# max32665 register map
Vendor: Maxim-Integrated; Series: ARMCM3; File version: 1.0
CPU: CM4 r2p1, little endian, MPU, FPU, 3 interrupt priority bits
Registers are 32-bit, read-write, reset 0x0 unless marked. A register's access mark holds for its fields unless they carry their own. Offsets are from the block's base; [hi:lo] are bit positions; {n}, {i} and the like mark numbered series; 'fields as' and 'values as' point back to an identical list.

## PTG — Pulse Train Generation
Base 0x4003C000
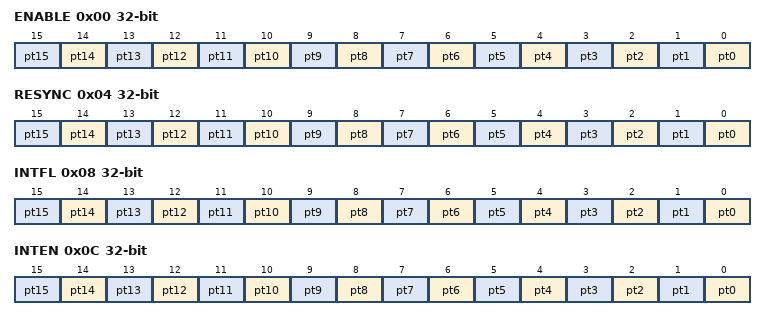
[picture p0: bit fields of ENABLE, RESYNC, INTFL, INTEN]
0x00 ENABLE — Global Enable/Disable Controls for All Pulse Trains
  [n] pt{n} (n=0..15) — Enable/Disable control for PT{n}
0x04 RESYNC — Global Resync (All Pulse Trains) Control
  [n] pt{n} (n=0..15) — Resync control for PT{n}
0x08 INTFL — Pulse Train Interrupt Flags
  [n] pt{n} (n=0..15) — Pulse Train {n} Stopped Interrupt Flag
0x0C INTEN — Pulse Train Interrupt Enable/Disable
  [n] pt{n} (n=0..15) — Pulse Train {n} Stopped Interrupt Enable/Disable
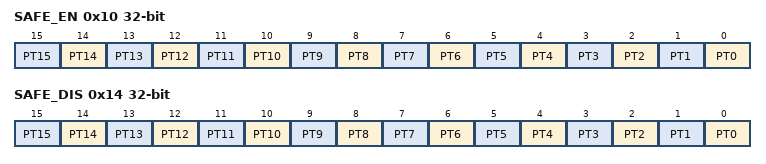
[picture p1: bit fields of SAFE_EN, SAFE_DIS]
0x10 SAFE_EN wo — Pulse Train Global Safe Enable.
  [n] PT{n} (n=0..15)
0x14 SAFE_DIS wo — Pulse Train Global Safe Disable.
  [n] PT{n} (n=0..15)

## SEMA — The Semaphore peripheral allows multiple cores in a system to cooperate when accessing shred resources. The peripheral contains eight semaphores that can be atomically set and cleared. It is left to the discretion of the software architect to decide how and when the semaphores are used and how they are allocated. Existing hardware does not have to be modified for this type of cooperative sharing, and the use of semaphores is exclusively within the software domain.
Base 0x4003E000
{0x0+4i} SEMAPHORES[{i}] (i=0..7) — Read to test and set, returns prior value. Write 0 to clear semaphore.
  [0] sema
0x100 status — Semaphore status bits. 0 indicates the semaphore is free, 1 indicates taken.
  [7:0] STATUS

## SIMO — Single Inductor Multiple Output Switching Converter
Base 0x40004400
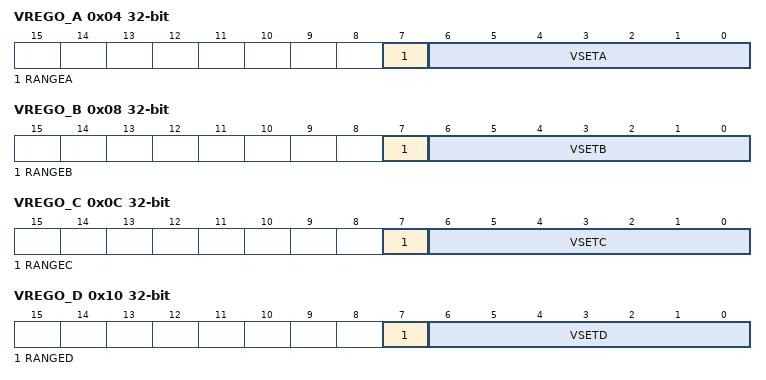
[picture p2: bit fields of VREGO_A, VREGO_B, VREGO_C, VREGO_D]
0x04 VREGO_A — Buck Voltage Regulator A Control Register
  [7] RANGEA — Regulator Output Range Set
    0=low (Low output voltage range); 1=High output voltage range
  [6:0] VSETA — Regulator Output Voltage Setting
0x08 VREGO_B — Buck Voltage Regulator B Control Register
  [7] RANGEB — Regulator Output Range Set
    values as VREGO_A.RANGEA
  [6:0] VSETB — Regulator Output Voltage Setting
0x0C VREGO_C — Buck Voltage Regulator C Control Register
  [7] RANGEC — Regulator Output Range Set
    values as VREGO_A.RANGEA
  [6:0] VSETC — Regulator Output Voltage Setting
0x10 VREGO_D — Buck Voltage Regulator D Control Register
  [7] RANGED — Regulator Output Range Set
    values as VREGO_A.RANGEA
  [6:0] VSETD — Regulator Output Voltage Setting
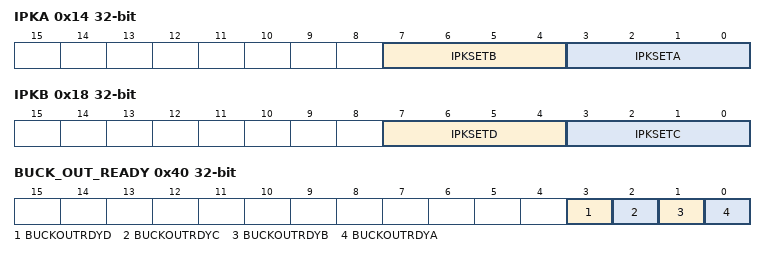
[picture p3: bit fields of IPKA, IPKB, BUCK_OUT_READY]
0x14 IPKA — High Side FET Peak Current VREGO_A/VREGO_B Register
  [7:4] IPKSETB — Voltage Regulator Peak Current Setting
  [3:0] IPKSETA — Voltage Regulator Peak Current Setting
0x18 IPKB — High Side FET Peak Current VREGO_C/VREGO_D Register
  [7:4] IPKSETD — Voltage Regulator Peak Current Setting
  [3:0] IPKSETC — Voltage Regulator Peak Current Setting
0x1C MAXTON — Maximum High Side FET Time On Register
  [3:0] TONSET — Sets the maximum on time for the high side FET, each increment represents 500ns
0x20 ILOAD_A ro — Buck Cycle Count VREGO_A Register
  [7:0] ILOADA — Number of buck cycles that occur within the cycle clock
0x24 ILOAD_B ro — Buck Cycle Count VREGO_B Register
  [7:0] ILOADB — Number of buck cycles that occur within the cycle clock
0x28 ILOAD_C ro — Buck Cycle Count VREGO_C Register
  [7:0] ILOADC — Number of buck cycles that occur within the cycle clock
0x2C ILOAD_D ro — Buck Cycle Count VREGO_D Register
  [7:0] ILOADD — Number of buck cycles that occur within the cycle clock
0x30 BUCK_ALERT_THR_A — Buck Cycle Count Alert VERGO_A Register
  [7:0] BUCKTHRA — Threshold for ILOADA to generate the BUCK_ALERT
0x34 BUCK_ALERT_THR_B — Buck Cycle Count Alert VERGO_B Register
  [7:0] BUCKTHRB — Threshold for ILOADB to generate the BUCK_ALERT
0x38 BUCK_ALERT_THR_C — Buck Cycle Count Alert VERGO_C Register
  [7:0] BUCKTHRC — Threshold for ILOADC to generate the BUCK_ALERT
0x3C BUCK_ALERT_THR_D — Buck Cycle Count Alert VERGO_D Register
  [7:0] BUCKTHRD — Threshold for ILOADD to generate the BUCK_ALERT
0x40 BUCK_OUT_READY ro — Buck Regulator Output Ready Register
  [all] fields
    0=notrdy (Output voltage not in range); 1=rdy (Output voltage in range)
  [3] BUCKOUTRDYD — When set, indicates that the output voltage has reached its regulated value
  [2] BUCKOUTRDYC — When set, indicates that the output voltage has reached its regulated value
  [1] BUCKOUTRDYB — When set, indicates that the output voltage has reached its regulated value
  [0] BUCKOUTRDYA — When set, indicates that the output voltage has reached its regulated value
0x44 ZERO_CROSS_CAL_A ro — Zero Cross Calibration VERGO_A Register
  [3:0] ZXCALA — Zero Cross Calibrartion Value VREGO_A
0x48 ZERO_CROSS_CAL_B ro — Zero Cross Calibration VERGO_B Register
  [3:0] ZXCALB — Zero Cross Calibrartion Value VREGO_B
0x4C ZERO_CROSS_CAL_C ro — Zero Cross Calibration VERGO_C Register
  [3:0] ZXCALC — Zero Cross Calibrartion Value VREGO_C
0x50 ZERO_CROSS_CAL_D ro — Zero Cross Calibration VERGO_D Register
  [3:0] ZXCALD — Zero Cross Calibrartion Value VREGO_D
